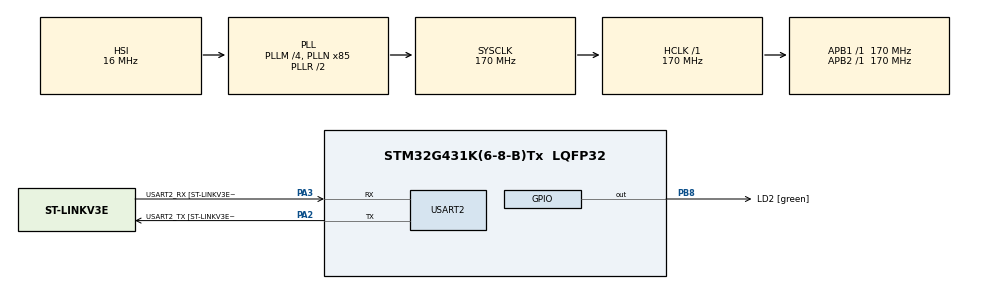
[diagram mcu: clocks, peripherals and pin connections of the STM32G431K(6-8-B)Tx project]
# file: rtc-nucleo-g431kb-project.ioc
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Mcu.Family=STM32G4
Mcu.Name=STM32G431K(6-8-B)Tx
Mcu.Package=LQFP32
NVIC.PriorityGroup=NVIC_PRIORITYGROUP_4
NVIC.RTC_Alarm_IRQn=true\:0\:0\:false\:false\:true\:true\:true\:true
PA13.GPIO_Label=T_SWDIO
PA13.Mode=Serial_Wire
PA13.Signal=SYS_JTMS-SWDIO
PA14.GPIO_Label=T_SWCLK
PA14.Mode=Serial_Wire
PA14.Signal=SYS_JTCK-SWCLK
PA2.GPIO_Label=USART2_TX [ST-LINKV3E_VCP_RX]
PA2.Mode=Asynchronous
PA2.Signal=USART2_TX
PA3.GPIO_Label=USART2_RX [ST-LINKV3E_VCP_TX]
PA3.Mode=Asynchronous
PA3.Signal=USART2_RX
PB3.GPIO_Label=T_SWO
PB3.Signal=SYS_JTDO-SWO
PB8-BOOT0.GPIO_Label=LD2 [green]
PB8-BOOT0.Signal=GPIO_Output
PF0-OSC_IN.Mode=HSE-External-Clock-Source
PF0-OSC_IN.Signal=RCC_OSC_IN
ProjectManager.HeapSize=0x200
ProjectManager.StackSize=0x400
ProjectManager.TargetToolchain=STM32CubeIDE
RCC.ADC12Freq_Value=170000000
RCC.AHBFreq_Value=170000000
RCC.APB1Freq_Value=170000000
RCC.APB1TimFreq_Value=170000000
RCC.APB2Freq_Value=170000000
RCC.APB2TimFreq_Value=170000000
RCC.CortexFreq_Value=170000000
RCC.EXTERNAL_CLOCK_VALUE=12288000
RCC.HCLKFreq_Value=170000000
RCC.HSE_VALUE=8000000
RCC.HSI48_VALUE=48000000
RCC.HSI_VALUE=16000000
RCC.LSE_VALUE=32768
RCC.PLLM=RCC_PLLM_DIV4
RCC.PLLN=85
RCC.SYSCLKFreq_VALUE=170000000
RCC.SYSCLKSource=RCC_SYSCLKSOURCE_PLLCLK
RCC.USBFreq_Value=170000000
RCC.VCOOutputFreq_Value=340000000
RTC.Alarm=RTC_ALARM_A
RTC.Date=14
RTC.Hours=23
RTC.Hours_A=23
RTC.Minutes=26
RTC.Minutes_A=30
RTC.Month=RTC_MONTH_SEPTEMBER
RTC.Seconds=20
RTC.Seconds_A=30
RTC.WeekDay=RTC_WEEKDAY_THURSDAY
RTC.Year=23
USART2.VirtualMode-Asynchronous=VM_ASYNC
USART2.WordLength=WORDLENGTH_8B
VP_RTC_VS_RTC_Activate.Mode=RTC_Enabled
VP_RTC_VS_RTC_Alarm_A_Intern.Mode=Alarm A
VP_RTC_VS_RTC_Calendar.Mode=RTC_Calendar
board=NUCLEO-G431KB

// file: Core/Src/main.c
/* USER CODE BEGIN Header */
/**
  ******************************************************************************
  * @file           : main.c
  * @brief          : Main program body
  ******************************************************************************
  * @attention
  *
  * Copyright (c) 2023 STMicroelectronics.
  * All rights reserved.
  *
  * This software is licensed under terms that can be found in the LICENSE file
  * in the root directory of this software component.
  * If no LICENSE file comes with this software, it is provided AS-IS.
  *
  ******************************************************************************
  */
/* USER CODE END Header */
#include "main.h"

/* USER CODE BEGIN Includes */
#include<stdio.h>
#include"internal_rtc.h"
/* USER CODE END Includes */

RTC_HandleTypeDef hrtc;

UART_HandleTypeDef huart2;

void SystemClock_Config(void);
static void MX_GPIO_Init(void);
static void MX_USART2_UART_Init(void);
static void MX_RTC_Init(void);
/* USER CODE BEGIN PFP */
// Declare a function named __io_putchar that takes in an integer parameter named ch and returns an integer
int __io_putchar(int ch);

/*
 * The __io_putchar function is used to transmit a single character over UART.
 * It takes in an integer parameter ch which represents the character to be transmitted.
 * The function calls HAL_UART_Transmit to transmit the character over UART2.
 * The parameters for HAL_UART_Transmit are a pointer to UART2 handle (&huart2), a pointer to the character to be transmitted ((uint8_t *)&ch), the size of the data to be transmitted (1), and a timeout value (0xffff).
 * After transmitting the character, the function returns the same character.
 * This function is typically used for low-level operations such as implementing printf functionality over UART.
 * */
// Define the function __io_putchar
int __io_putchar(int ch)
{
    // Call HAL_UART_Transmit with parameters &huart2, (uint8_t *)&ch, 1, and 0xffff
    HAL_UART_Transmit(&huart2, (uint8_t *)&ch, 1, 0xffff);
    return ch; // Return the character that was transmitted
}
/* USER CODE END PFP */

int main(void)
{

  /* MCU Configuration--------------------------------------------------------*/

  /* Reset of all peripherals, Initializes the Flash interface and the Systick. */
  HAL_Init();

  /* Configure the system clock */
  SystemClock_Config();

  /* Initialize all configured peripherals */
  MX_GPIO_Init();
  MX_USART2_UART_Init();
  MX_RTC_Init();
  /* USER CODE BEGIN 2 */
  // Set the time to 23:59:30 and the date to 2023-09-14 (Thursday)
  set_time(0x23, 0x59, 0x30, 0x04, 0x09, 0x14, 0x23);
  // Set an alarm for 00:00:05 on the 15th of the month
  set_alarm (0x00, 0x00, 0x05, 0x15);
  /* USER CODE END 2 */

  /* Infinite loop */
  /* USER CODE BEGIN WHILE */
  while (1)
  {
	  // Call the get_time function to get the current time and date from the Real-Time Clock (RTC)
	  get_time();
	  // Delay the program execution for 1000 milliseconds (1 second)
	  HAL_Delay(1000);
    /* USER CODE END WHILE */

  }
}

void SystemClock_Config(void)
{
  RCC_OscInitTypeDef RCC_OscInitStruct = {0};
  RCC_ClkInitTypeDef RCC_ClkInitStruct = {0};

  /** Configure the main internal regulator output voltage
  */
  HAL_PWREx_ControlVoltageScaling(PWR_REGULATOR_VOLTAGE_SCALE1_BOOST);

  /** Initializes the RCC Oscillators according to the specified parameters
  * in the RCC_OscInitTypeDef structure.
  */
  RCC_OscInitStruct.OscillatorType = RCC_OSCILLATORTYPE_HSI|RCC_OSCILLATORTYPE_LSI;
  RCC_OscInitStruct.HSIState = RCC_HSI_ON;
  RCC_OscInitStruct.HSICalibrationValue = RCC_HSICALIBRATION_DEFAULT;
  RCC_OscInitStruct.LSIState = RCC_LSI_ON;
  RCC_OscInitStruct.PLL.PLLState = RCC_PLL_ON;
  RCC_OscInitStruct.PLL.PLLSource = RCC_PLLSOURCE_HSI;
  RCC_OscInitStruct.PLL.PLLM = RCC_PLLM_DIV4;
  RCC_OscInitStruct.PLL.PLLN = 85;
  RCC_OscInitStruct.PLL.PLLP = RCC_PLLP_DIV2;
  RCC_OscInitStruct.PLL.PLLQ = RCC_PLLQ_DIV2;
  RCC_OscInitStruct.PLL.PLLR = RCC_PLLR_DIV2;
  if (HAL_RCC_OscConfig(&RCC_OscInitStruct) != HAL_OK)
  {
    Error_Handler();
  }

  /** Initializes the CPU, AHB and APB buses clocks
  */
  RCC_ClkInitStruct.ClockType = RCC_CLOCKTYPE_HCLK|RCC_CLOCKTYPE_SYSCLK
                              |RCC_CLOCKTYPE_PCLK1|RCC_CLOCKTYPE_PCLK2;
  RCC_ClkInitStruct.SYSCLKSource = RCC_SYSCLKSOURCE_PLLCLK;
  RCC_ClkInitStruct.AHBCLKDivider = RCC_SYSCLK_DIV1;
  RCC_ClkInitStruct.APB1CLKDivider = RCC_HCLK_DIV1;
  RCC_ClkInitStruct.APB2CLKDivider = RCC_HCLK_DIV1;

  if (HAL_RCC_ClockConfig(&RCC_ClkInitStruct, FLASH_LATENCY_4) != HAL_OK)
  {
    Error_Handler();
  }
}

static void MX_RTC_Init(void)
{

  RTC_TimeTypeDef sTime = {0};
  RTC_DateTypeDef sDate = {0};
  RTC_AlarmTypeDef sAlarm = {0};

  /** Initialize RTC Only
  */
  hrtc.Instance = RTC;
  hrtc.Init.HourFormat = RTC_HOURFORMAT_24;
  hrtc.Init.AsynchPrediv = 127;
  hrtc.Init.SynchPrediv = 255;
  hrtc.Init.OutPut = RTC_OUTPUT_DISABLE;
  hrtc.Init.OutPutRemap = RTC_OUTPUT_REMAP_NONE;
  hrtc.Init.OutPutPolarity = RTC_OUTPUT_POLARITY_HIGH;
  hrtc.Init.OutPutType = RTC_OUTPUT_TYPE_OPENDRAIN;
  hrtc.Init.OutPutPullUp = RTC_OUTPUT_PULLUP_NONE;
  if (HAL_RTC_Init(&hrtc) != HAL_OK)
  {
    Error_Handler();
  }

  /** Initialize RTC and set the Time and Date
  */
  sTime.Hours = 0x23;
  sTime.Minutes = 0x26;
  sTime.Seconds = 0x20;
  sTime.SubSeconds = 0x0;
  sTime.DayLightSaving = RTC_DAYLIGHTSAVING_NONE;
  sTime.StoreOperation = RTC_STOREOPERATION_RESET;
  if (HAL_RTC_SetTime(&hrtc, &sTime, RTC_FORMAT_BCD) != HAL_OK)
  {
    Error_Handler();
  }
  sDate.WeekDay = RTC_WEEKDAY_THURSDAY;
  sDate.Month = RTC_MONTH_SEPTEMBER;
  sDate.Date = 0x14;
  sDate.Year = 0x23;
  if (HAL_RTC_SetDate(&hrtc, &sDate, RTC_FORMAT_BCD) != HAL_OK)
  {
    Error_Handler();
  }

  /** Enable the Alarm A
  */
  sAlarm.AlarmTime.Hours = 0x23;
  sAlarm.AlarmTime.Minutes = 0x30;
  sAlarm.AlarmTime.Seconds = 0x30;
  sAlarm.AlarmTime.SubSeconds = 0x0;
  sAlarm.AlarmMask = RTC_ALARMMASK_NONE;
  sAlarm.AlarmSubSecondMask = RTC_ALARMSUBSECONDMASK_ALL;
  sAlarm.AlarmDateWeekDaySel = RTC_ALARMDATEWEEKDAYSEL_DATE;
  sAlarm.AlarmDateWeekDay = 0x1;
  sAlarm.Alarm = RTC_ALARM_A;
  if (HAL_RTC_SetAlarm_IT(&hrtc, &sAlarm, RTC_FORMAT_BCD) != HAL_OK)
  {
    Error_Handler();
  }

}

static void MX_USART2_UART_Init(void)
{

  huart2.Instance = USART2;
  huart2.Init.BaudRate = 115200;
  huart2.Init.WordLength = UART_WORDLENGTH_8B;
  huart2.Init.StopBits = UART_STOPBITS_1;
  huart2.Init.Parity = UART_PARITY_NONE;
  huart2.Init.Mode = UART_MODE_TX_RX;
  huart2.Init.HwFlowCtl = UART_HWCONTROL_NONE;
  huart2.Init.OverSampling = UART_OVERSAMPLING_16;
  huart2.Init.OneBitSampling = UART_ONE_BIT_SAMPLE_DISABLE;
  huart2.Init.ClockPrescaler = UART_PRESCALER_DIV1;
  huart2.AdvancedInit.AdvFeatureInit = UART_ADVFEATURE_NO_INIT;
  if (HAL_UART_Init(&huart2) != HAL_OK)
  {
    Error_Handler();
  }
  if (HAL_UARTEx_SetTxFifoThreshold(&huart2, UART_TXFIFO_THRESHOLD_1_8) != HAL_OK)
  {
    Error_Handler();
  }
  if (HAL_UARTEx_SetRxFifoThreshold(&huart2, UART_RXFIFO_THRESHOLD_1_8) != HAL_OK)
  {
    Error_Handler();
  }
  if (HAL_UARTEx_DisableFifoMode(&huart2) != HAL_OK)
  {
    Error_Handler();
  }

}

static void MX_GPIO_Init(void)
{
  GPIO_InitTypeDef GPIO_InitStruct = {0};

  /* GPIO Ports Clock Enable */
  __HAL_RCC_GPIOF_CLK_ENABLE();
  __HAL_RCC_GPIOA_CLK_ENABLE();
  __HAL_RCC_GPIOB_CLK_ENABLE();

  /*Configure GPIO pin Output Level */
  HAL_GPIO_WritePin(LD2_GPIO_Port, LD2_Pin, GPIO_PIN_RESET);

  /*Configure GPIO pin : LD2_Pin */
  GPIO_InitStruct.Pin = LD2_Pin;
  GPIO_InitStruct.Mode = GPIO_MODE_OUTPUT_PP;
  GPIO_InitStruct.Pull = GPIO_NOPULL;
  GPIO_InitStruct.Speed = GPIO_SPEED_FREQ_LOW;
  HAL_GPIO_Init(LD2_GPIO_Port, &GPIO_InitStruct);

}

void Error_Handler(void)
{
  __disable_irq();
  while (1)
  {
  }
}
